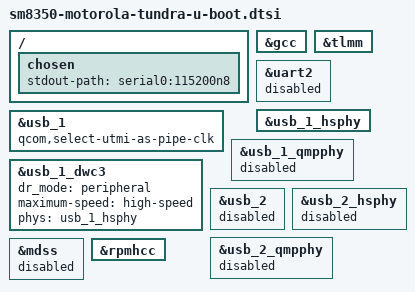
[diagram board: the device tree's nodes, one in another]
// SPDX-License-Identifier: GPL-2.0

/ {
	chosen {
		stdout-path = "serial0:115200n8";
	};
};

&gcc {
	bootph-all;
};

&tlmm {
	bootph-all;
};

&uart2 {
	bootph-all;
	status = "disabled";
};

&usb_1 {
	qcom,select-utmi-as-pipe-clk;
	bootph-all;
};

&usb_1_hsphy {
	bootph-all;
};

&usb_1_qmpphy {
	status = "disabled";
};

&usb_1_dwc3 {
	dr_mode = "peripheral";
	maximum-speed = "high-speed";
	phys = <&usb_1_hsphy>;
	phy-names = "usb2-phy";
	bootph-all;
};

&usb_2 {
	status = "disabled";
};

&usb_2_hsphy {
	status = "disabled";
};

&usb_2_qmpphy {
	status = "disabled";
};

&mdss {
	status = "disabled";
};

&rpmhcc {
	bootph-all;
};
